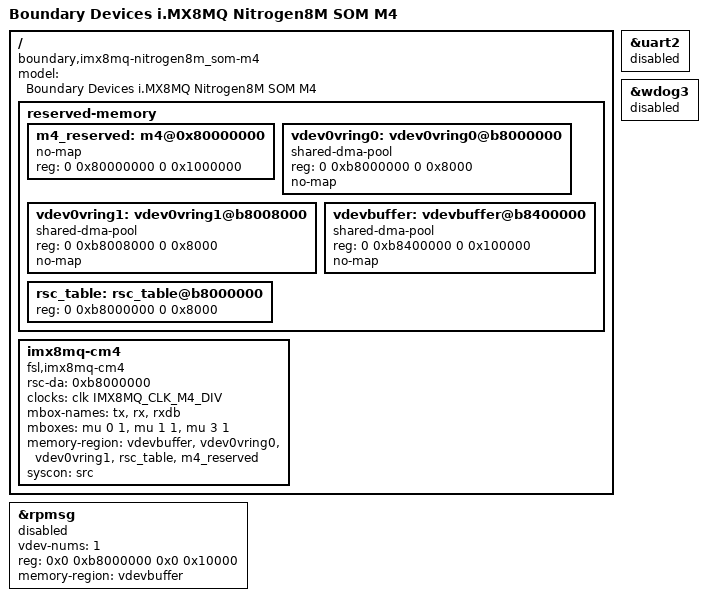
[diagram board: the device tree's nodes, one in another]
// SPDX-License-Identifier: (GPL-2.0+ OR MIT)
/*
 * Copyright 2018 Boundary Devices
 */

#include "imx8mq-nitrogen8m_som.dts"

/ {
	model = "Boundary Devices i.MX8MQ Nitrogen8M SOM M4";
	compatible = "boundary,imx8mq-nitrogen8m_som-m4", "fsl,imx8mq";

	reserved-memory {
		#address-cells = <2>;
		#size-cells = <2>;
		ranges;

		m4_reserved: m4@0x80000000 {
			no-map;
			reg = <0 0x80000000 0 0x1000000>;
		};

		vdev0vring0: vdev0vring0@b8000000 {
			compatible = "shared-dma-pool";
			reg = <0 0xb8000000 0 0x8000>;
			no-map;
		};

		vdev0vring1: vdev0vring1@b8008000 {
			compatible = "shared-dma-pool";
			reg = <0 0xb8008000 0 0x8000>;
			no-map;
		};

		vdevbuffer: vdevbuffer@b8400000 {
			compatible = "shared-dma-pool";
			reg = <0 0xb8400000 0 0x100000>;
			no-map;
		};

		rsc_table: rsc_table@b8000000 {
			reg = <0 0xb8000000 0 0x8000>;
		};
	};

	imx8mq-cm4 {
		compatible = "fsl,imx8mq-cm4";
		rsc-da = <0xb8000000>;
		clocks = <&clk IMX8MQ_CLK_M4_DIV>;
		mbox-names = "tx", "rx", "rxdb";
		mboxes = <&mu 0 1
			  &mu 1 1
			  &mu 3 1>;
		memory-region = <&vdevbuffer>, <&vdev0vring0>, <&vdev0vring1>,
				<&rsc_table>, <&m4_reserved>;
		syscon = <&src>;
	};
};

&rpmsg {
	/*
	 * 64K for one rpmsg instance:
	 * --0xb8000000~0xb800ffff: pingpong
	 */
	vdev-nums = <1>;
	reg = <0x0 0xb8000000 0x0 0x10000>;
	memory-region = <&vdevbuffer>;
	status = "disabled";
};

&uart2 {
	status = "disabled";
};

&wdog3 {
	status = "disabled";
};
